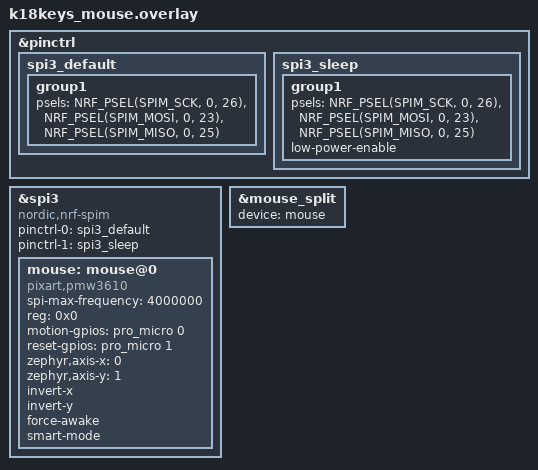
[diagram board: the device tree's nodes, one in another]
/*
* Copyright (c) 2020 Pete Johanson
*
* SPDX-License-Identifier: MIT
*/

#include "k18keys_mouse.dtsi"

&pinctrl {
    spi3_default: spi3_default {
        group1 {
            psels = <NRF_PSEL(SPIM_SCK, 0, 26)>,
                    <NRF_PSEL(SPIM_MOSI, 0, 23)>,
                    <NRF_PSEL(SPIM_MISO, 0, 25)>;
        };
    };

    spi3_sleep: spi3_sleep {
        group1 {
            psels = <NRF_PSEL(SPIM_SCK, 0, 26)>,
                    <NRF_PSEL(SPIM_MOSI, 0, 23)>,
                    <NRF_PSEL(SPIM_MISO, 0, 25)>;
                    low-power-enable;
        };
    };
};

&spi3 {
    compatible = "nordic,nrf-spim";
    status = "okay";

    pinctrl-0 = <&spi3_default>;
    pinctrl-1 = <&spi3_sleep>;
    pinctrl-names = "default", "sleep";

    mouse: mouse@0 {
        compatible = "pixart,pmw3610";
        spi-max-frequency = <4000000>;
        reg = <0x0>;
        motion-gpios = <&pro_micro 0 GPIO_ACTIVE_HIGH>;
        reset-gpios = <&pro_micro 1 GPIO_ACTIVE_HIGH>;
        zephyr,axis-x = <0>;
        zephyr,axis-y = <1>;
        invert-x;
        invert-y;
        force-awake;
        smart-mode;
    };
};

&mouse_split {
    device = <&mouse>;
    /* input-processors = <&zip_xy_transform (INPUT_TRANSFORM_XY_SWAP | INPUT_TRANSFORM_X_INVERT | INPUT_TRANSFORM_Y_INVERT)>; */
};
